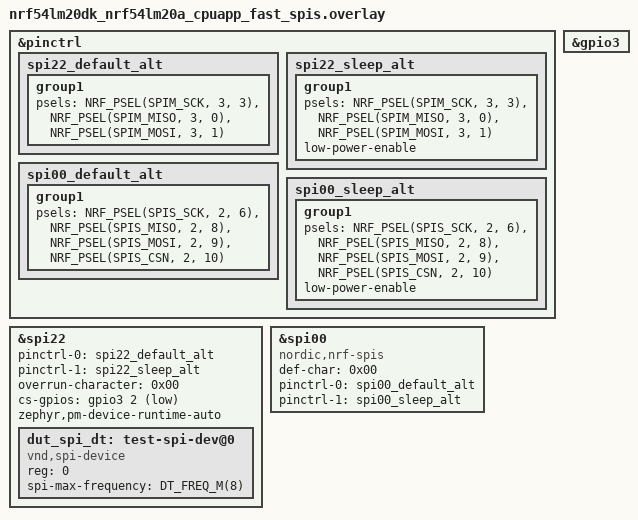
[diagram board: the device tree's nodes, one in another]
/*
 * Copyright (c) 2026 Nordic Semiconductor ASA
 *
 * SPDX-License-Identifier: LicenseRef-Nordic-5-Clause
 */

/*
 * Required loopbacks:
 * P2.06 (SCK) - P3.03 (clock pin)
 * P2.09 (MOSI) - P3.01
 * P2.08 (MISO) - P3.00
 * P2.10 (CS) - P3.02
 */

&pinctrl {
	spi22_default_alt: spi22_default_alt {
		group1 {
			psels = <NRF_PSEL(SPIM_SCK, 3, 3)>,
				<NRF_PSEL(SPIM_MISO, 3, 0)>,
				<NRF_PSEL(SPIM_MOSI, 3, 1)>;
		};
	};

	spi22_sleep_alt: spi22_sleep_alt {
		group1 {
			psels = <NRF_PSEL(SPIM_SCK, 3, 3)>,
				<NRF_PSEL(SPIM_MISO, 3, 0)>,
				<NRF_PSEL(SPIM_MOSI, 3, 1)>;
			low-power-enable;
		};
	};

	spi00_default_alt: spi00_default_alt {
		group1 {
			psels = <NRF_PSEL(SPIS_SCK, 2, 6)>,
				<NRF_PSEL(SPIS_MISO, 2, 8)>,
				<NRF_PSEL(SPIS_MOSI, 2, 9)>,
				<NRF_PSEL(SPIS_CSN, 2, 10)>;
		};
	};

	spi00_sleep_alt: spi00_sleep_alt {
		group1 {
			psels = <NRF_PSEL(SPIS_SCK, 2, 6)>,
				<NRF_PSEL(SPIS_MISO, 2, 8)>,
				<NRF_PSEL(SPIS_MOSI, 2, 9)>,
				<NRF_PSEL(SPIS_CSN, 2, 10)>;
			low-power-enable;
		};
	};
};

&gpio3 {
	status = "okay";
};

&spi22 {
	status = "okay";
	pinctrl-0 = <&spi22_default_alt>;
	pinctrl-1 = <&spi22_sleep_alt>;
	pinctrl-names = "default", "sleep";
	overrun-character = <0x00>;
	cs-gpios = <&gpio3 2 GPIO_ACTIVE_LOW>;
	zephyr,pm-device-runtime-auto;

	dut_spi_dt: test-spi-dev@0 {
		compatible = "vnd,spi-device";
		reg = <0>;
		spi-max-frequency = <DT_FREQ_M(8)>;
	};
};

dut_spis: &spi00 {
	compatible = "nordic,nrf-spis";
	status = "okay";
	def-char = <0x00>;
	pinctrl-0 = <&spi00_default_alt>;
	pinctrl-1 = <&spi00_sleep_alt>;
	pinctrl-names = "default", "sleep";
	/delete-property/ rx-delay-supported;
	/delete-property/ rx-delay;
};
